# CONTROLSS_G2_EPWM20_CONTROLSS_G2_EPWM20 register map
Vendor: Texas Instruments
Registers are 16-bit, read-write, reset 0x0 unless marked. A register's access mark holds for its fields unless they carry their own. Offsets are as the file gives them; [hi:lo] are bit positions; {n}, {i} and the like mark numbered series.

## CONTROLSS_G2_EPWM20_CONTROLSS_G2_EPWM (part 4 of 4)
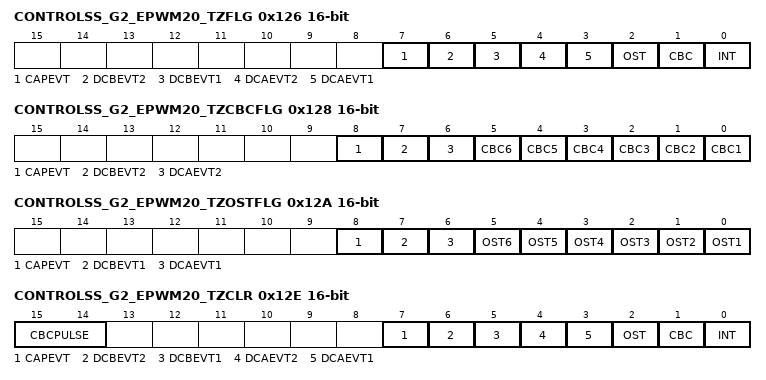
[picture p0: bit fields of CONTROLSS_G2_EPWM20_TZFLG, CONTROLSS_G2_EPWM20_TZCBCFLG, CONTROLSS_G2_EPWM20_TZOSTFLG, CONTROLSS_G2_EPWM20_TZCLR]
0x126 CONTROLSS_G2_EPWM20_TZFLG ro — Trip Zone Flag Register
  [7] CAPEVT — Latched Status Flag for Capture Event 0: Indicates no trip event has occurred on CAPEVT 1: Indicates a trip event has occurred for the event defined for CAPEVT
  [6] DCBEVT2 — Latched Status Flag for Digital Compare Output B Event 2 0: Indicates no trip event has occurred on DCBEVT2 1: Indicates a trip event has occurred for the event defined for DCBEVT2
  [5] DCBEVT1 — Latched Status Flag for Digital Compare Output B Event 1 0: Indicates no trip event has occurred on DCBEVT1 1: Indicates a trip event has occurred for the event defined for DCBEVT1
  [4] DCAEVT2 — Latched Status Flag for Digital Compare Output A Event 2 0: Indicates no trip event has occurred on DCAEVT2 1: Indicates a trip event has occurred for the event defined for DCAEVT2
  [3] DCAEVT1 — Latched Status Flag for Digital Compare Output A Event 1 0: Indicates no trip event has occurred on DCAEVT1 1: Indicates a trip event has occurred for the event defined for DCAEVT1
  [2] OST — Latched Status Flag for A One-Shot Trip Event 0: No one-shot trip event has occurred. 1: Indicates a trip event has occurred on a pin selected as a one-shot trip source. This bit is cleared by writing the appropriate value to the TZCLR register.
  [1] CBC — Latched Status Flag for Cycle-By-Cycle Trip Event 0: No cycle-by-cycle trip event has occurred. 1: Indicates a trip event has occurred on a signal selected as a cycle-by-cycle trip source. The TZFLG[CBC] bit will remain set until it is manually cleared by the user. If the cycle-by-cycle trip event is still present when the CBC bit is cleared, then CBC will be immediately set again. The specified condition on the signal is automatically cleared when the ePWM time-base counter reaches zero [TBCTR = 0x00] if the trip condition is no longer present. The condition on the signal is only cleared when the TBCTR = 0x00 no matter where in the cycle the CBC flag is cleared. This bit is cleared by writing the appropriate value to the TZCLR register.
  [0] INT — Latched Trip Interrupt Status Flag 0: Indicates no interrupt has been generated. 1: Indicates an EPWMx_TZINT PIE interrupt was generated because of a trip condition. No further EPWMx_TZINT PIE interrupts will be generated until this flag is cleared. If the interrupt flag is cleared when either CBC or OST is set, then another interrupt pulse will be generated. Clearing all flag bits will prevent further interrupts. This bit is cleared by writing the appropriate value to the TZCLR register.
0x128 CONTROLSS_G2_EPWM20_TZCBCFLG ro — Trip Zone CBC Flag Register
  [8] CAPEVT — Latched Status Flag for Capture Event 0: Indicates no trip event has occurred on CAPEVT 1: Indicates a trip event has occurred for the event defined for CAPEVT
  [7] DCBEVT2 — Latched Status Flag for Digital Compare B Output Event 2 Trip Latch 0: Reading a 0 indicates that no trip has occurred on DCBEVT2. 1: Reading a 1 indicates a trip has occured on the DCBEVT2 selected event.
  [6] DCAEVT2 — Latched Status Flag for Digital Compare A Output Event 2 Trip Latch 0: Reading a 0 indicates that no trip has occurred on DCAEVT2. 1: Reading a 1 indicates a trip has occured on the DCAEVT2 selected event.
  [n-1] CBC{n} (n=1..6) — Latched Status Flag for CBC{n} Trip Latch 0: Reading a 0 indicates that no trip has occurred on CBC{n}. 1: Reading a 1 indicates a trip has occured on the CBC{n} selected event.
0x12A CONTROLSS_G2_EPWM20_TZOSTFLG ro — Trip Zone OST Flag Register
  [8] CAPEVT — Latched Status Flag for Capture Event 0: Indicates no trip event has occurred on CAPEVT 1: Indicates a trip event has occurred for the event defined for CAPEVT
  [7] DCBEVT1 — Latched Status Flag for Digital Compare B Output Event 1 Trip Latch 0: Reading a 0 indicates that no trip has occurred on DCBEVT1. 1: Reading a 1 indicates a trip has occured on the DCBEVT1 selected event.
  [6] DCAEVT1 — Latched Status Flag for Digital Compare A Output Event 1 Trip Latch 0: Reading a 0 indicates that no trip has occurred on DCAEVT1. 1: Reading a 1 indicates a trip has occured on the DCAEVT1 selected event.
  [n-1] OST{n} (n=1..6) — Latched Status Flag for OST{n} Trip Latch 0: Reading a 0 indicates that no trip has occurred on OST{n}. 1: Reading a 1 indicates a trip has occured on the OST{n} selected event.
0x12E CONTROLSS_G2_EPWM20_TZCLR access not given — Trip Zone Clear Register
  [15:14] CBCPULSE rw — Clear Pulse for Cycle-By-Cycle [CBC] Trip Latch This bit field determines which pulse clears the CBC trip latch. 00: CTR = zero pulse clears CBC trip latch. [Same as legacy designs.] 01: CTR = PRD pulse clears CBC trip latch. 10: CTR = zero or CTR = PRD pulse clears CBC trip latch. 11: CBC trip latch is not cleared
  [7] CAPEVT — Clear Flag for Capture Event 0: Writing 0 has no effect. This bit always reads back 0. 1: Writing 1 clears the CAPEVT event trip condition. (access R/W1TS)
  [6] DCBEVT2 — Clear Flag for Digital Compare Output B Event 2 0: Writing 0 has no effect. This bit always reads back 0. 1: Writing 1 clears the DCBEVT2 event trip condition. (access R/W1TS)
  [5] DCBEVT1 — Clear Flag for Digital Compare Output B Event 1 0: Writing 0 has no effect. This bit always reads back 0. 1: Writing 1 clears the DCBEVT1 event trip condition. (access R/W1TS)
  [4] DCAEVT2 — Clear Flag for Digital Compare Output A Event 2 0: Writing 0 has no effect. This bit always reads back 0. 1: Writing 1 clears the DCAEVT2 event trip condition. (access R/W1TS)
  [3] DCAEVT1 — Clear Flag for Digital Compare Output A Event 1 0: Writing 0 has no effect. This bit always reads back 0. 1: Writing 1 clears the DCAEVT1 event trip condition. (access R/W1TS)
  [2] OST — Clear Flag for One-Shot Trip [OST] Latch 0: Has no effect. Always reads back a 0. 1: Clears this Trip [set] condition. (access R/W1TS)
  [1] CBC — Clear Flag for Cycle-By-Cycle [CBC] Trip Latch 0: Has no effect. Always reads back a 0. 1: Clears this Trip [set] condition. (access R/W1TS)
  [0] INT — Global Interrupt Clear Flag 0: Has no effect. Always reads back a 0. 1: Clears the trip-interrupt flag for this ePWM module [TZFLG[INT]]. NOTE: No further EPWMx_TZINT PIE interrupts will be generated until the flag is cleared. If the TZFLG[INT] bit is cleared and any of the other flag bits are set, then another interrupt pulse will be generated. Clearing all flag bits will prevent further interrupts. (access R/W1TS)
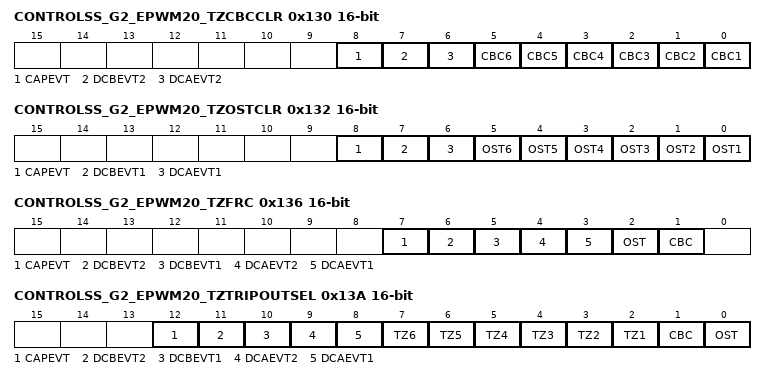
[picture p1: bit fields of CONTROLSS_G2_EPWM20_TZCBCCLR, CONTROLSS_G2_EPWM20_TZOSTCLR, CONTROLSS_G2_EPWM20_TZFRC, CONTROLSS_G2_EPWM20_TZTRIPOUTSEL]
0x130 CONTROLSS_G2_EPWM20_TZCBCCLR access not given — Trip Zone CBC Clear Register
  [8] CAPEVT — Clear Flag for CAPEVT selected for CBC 0: Writing a 0 has no effect. 1: Writing a 1 will clear the TZCBCFLG[CAPEVT] bit. (access R/W1TS)
  [7] DCBEVT2 — Clear Flag for Digital Compare Output B Event 2 selected for CBC 0: Writing a 0 has no effect. 1: Writing a 1 will clear the TZCBCFLG[DCBEVT2] bit. (access R/W1TS)
  [6] DCAEVT2 — Clear Flag for Digital Compare Output A Event 2 selected for CBC 0: Writing a 0 has no effect. 1: Writing a 1 will clear the TZCBCFLG[DCAEVT2] bit. (access R/W1TS)
  [n-1] CBC{n} (n=1..6) — Clear Flag for Cycle-By-Cycle [CBC{n}] Trip Latch 0: Writing a 0 has no effect. 1: Writing a 1 will clear the TZCBCFLG[CBC{n}] bit. (access R/W1TS)
0x132 CONTROLSS_G2_EPWM20_TZOSTCLR access not given — Trip Zone OST Clear Register
  [8] CAPEVT — Clear Flag for CAPEVT selected for OST 0: Writing a 0 has no effect. 1: Writing a 1 will clear the TZOSTFLG[CAPEVT] bit. (access R/W1TS)
  [7] DCBEVT1 — Clear Flag for Digital Compare Output B Event 1 selected for OST 0: Writing a 0 has no effect. 1: Writing a 1 will clear the TZOSTFLG[DCBEVT1] bit. (access R/W1TS)
  [6] DCAEVT1 — Clear Flag for Digital Compare Output A Event 1 selected for OST 0: Writing a 0 has no effect. 1: Writing a 1 will clear the TZOSTFLG[DCAEVT1] bit. (access R/W1TS)
  [n-1] OST{n} (n=1..6) — Clear Flag for Oneshot [OST{n}] Trip Latch 0: Writing a 0 has no effect. 1: Writing a 1 will clear the TZOSTFLG[OST{n}] bit. (access R/W1TS)
0x136 CONTROLSS_G2_EPWM20_TZFRC access not given — Trip Zone Force Register
  [7] CAPEVT — Force Flag for Capture Event Output 0: Writing 0 has no effect. This bit always reads back 0. 1: Writing 1 forces the CAPEVT event trip condition and sets the TZFLG[CAPEVT] bit. (access R/W1TS)
  [6] DCBEVT2 — Force Flag for Digital Compare Output B Event 2 0: Writing 0 has no effect. This bit always reads back 0. 1: Writing 1 forces the DCBEVT2 event trip condition and sets the TZFLG[DCBEVT2] bit. (access R/W1TS)
  [5] DCBEVT1 — Force Flag for Digital Compare Output B Event 1 0: Writing 0 has no effect. This bit always reads back 0. 1: Writing 1 forces the DCBEVT1 event trip condition and sets the TZFLG[DCBEVT1] bit. (access R/W1TS)
  [4] DCAEVT2 — Force Flag for Digital Compare Output A Event 2 0: Writing 0 has no effect. This bit always reads back 0. 1: Writing 1 forces the DCAEVT2 event trip condition and sets the TZFLG[DCAEVT2] bit. (access R/W1TS)
  [3] DCAEVT1 — Force Flag for Digital Compare Output A Event 1 0: Writing 0 has no effect. This bit always reads back 0 1: Writing 1 forces the DCAEVT1 event trip condition and sets the TZFLG[DCAEVT1] bit. (access R/W1TS)
  [2] OST — Force a One-Shot Trip Event via Software 0: Writing of 0 is ignored. Always reads back a 0. 1: Forces a one-shot trip event and sets the TZFLG[OST] bit. (access R/W1TS)
  [1] CBC — Force a Cycle-by-Cycle Trip Event via Software 0: Writing of 0 is ignored. Always reads back a 0. 1: Forces a cycle-by-cycle trip event and sets the TZFLG[CBC] bit. (access R/W1TS)
0x13A CONTROLSS_G2_EPWM20_TZTRIPOUTSEL — Trip Zone Force Register
  [12] CAPEVT — CAPEVT Select 0: Disable TZ6 as a TRIPOUT source for this ePWM module 1: Enable TZ6 as a TRIPOUT source for this ePWM module
  [11] DCBEVT2 — DCBEVT2 Select 0: Disable TZ6 as a TRIPOUT source for this ePWM module 1: Enable TZ6 as a TRIPOUT source for this ePWM module
  [10] DCBEVT1 — DCBEVT1 Select 0: Disable TZ6 as a TRIPOUT source for this ePWM module 1: Enable TZ6 as a TRIPOUT source for this ePWM module
  [9] DCAEVT2 — DCAEVT2 Select 0: Disable TZ6 as a TRIPOUT source for this ePWM module 1: Enable TZ6 as a TRIPOUT source for this ePWM module
  [8] DCAEVT1 — DCAEVT1 Select 0: Disable TZ6 as a TRIPOUT source for this ePWM module 1: Enable TZ6 as a TRIPOUT source for this ePWM module
  [n+1] TZ{n} (n=1..6) — Trip-zone {n} [TZ{n}] Select 0: Disable TZ{n} as a TRIPOUT source for this ePWM module 1: Enable TZ{n} as a TRIPOUT source for this ePWM module
  [1] CBC — CBC Select 0: Disable TZ1 as a TRIPOUT source for this ePWM module 1: Enable TZ1 as a TRIPOUT source for this ePWM module
  [0] OST — OST Select 0: Disable TZ1 as a TRIPOUT source for this ePWM module 1: Enable TZ1 as a TRIPOUT source for this ePWM module
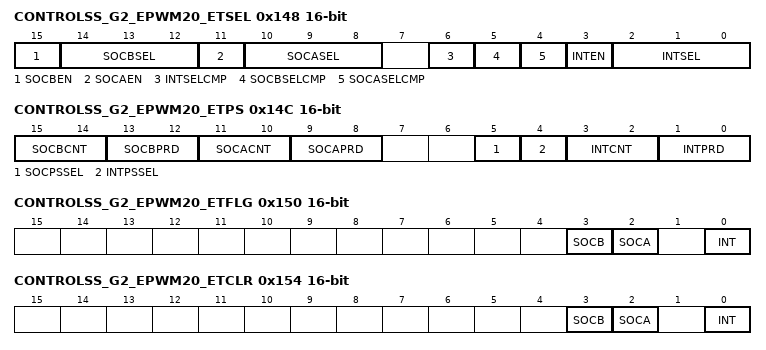
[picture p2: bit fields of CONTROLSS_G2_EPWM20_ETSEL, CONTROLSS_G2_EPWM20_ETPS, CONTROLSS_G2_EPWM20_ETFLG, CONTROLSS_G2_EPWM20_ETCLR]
0x148 CONTROLSS_G2_EPWM20_ETSEL — Event Trigger Selection Register
  [15] SOCBEN — Enable the ADC Start of Conversion B [EPWMxSOCB] Pulse 0: Disable EPWMxSOCB. 1: Enable EPWMxSOCB pulse.
  [14:12] SOCBSEL — EPWMxSOCB Selection Options These bits determine when a EPWMxSOCB pulse will be generated. 000: Enable DCBEVT1.soc event 001: Enable event time-base counter equal to zero. [TBCTR = 0x00] 010: Enable event time-base counter equal to period [TBCTR = TBPRD] 011: Enable event time-base counter based on mixed events [ETSOCBMIX]. ETSOCBMIX is configured in the ETSOCBMIXEN register. 100: Enable event time-base counter equal to CMPA when the timer is incrementing or CMPC when the timer is incrementing 101: Enable event time-base counter equal to CMPA when the timer is decrementing or CMPC when the timer is decrementing 110: Enable event: time-base counter equal to CMPB when the timer is incrementing or CMPD when the timer is incrementing 111: Enable event: time-base counter equal to CMPB when the timer is decrementing or CMPD when the timer is decrementing [*] Event selected is determined by SOCBSELCMP bit.
  [11] SOCAEN — Enable the ADC Start of Conversion A [EPWMxSOCA] Pulse 0: Disable EPWMxSOCA. 1: Enable EPWMxSOCA pulse.
  [10:8] SOCASEL — EPWMxSOCA Selection Options These bits determine when a EPWMxSOCA pulse will be generated. 000: Enable DCAEVT1.soc event 001: Enable event time-base counter equal to zero. [TBCTR = 0x00] 010: Enable event time-base counter equal to period [TBCTR = TBPRD] 011: Enable event time-base counter based on mixed events [ETSOCAMIX]. ETSOCAMIX is configured in the ETSOCAMIXEN register. 100: Enable event time-base counter equal to CMPA when the timer is incrementing or CMPC when the timer is incrementing 101: Enable event time-base counter equal to CMPA when the timer is decrementing or CMPC when the timer is decrementing 110: Enable event: time-base counter equal to CMPB when the timer is incrementing or CMPD when the timer is incrementing 111: Enable event: time-base counter equal to CMPB when the timer is decrementing or CMPD when the timer is decrementing [*] Event selected is determined by SOCASELCMP bit.
  [6] INTSELCMP — EPWMxINT Compare Register Selection Options 0: Enable event time-base counter equal to CMPA when the timer is incrementing / Enable event time-base counter equal to CMPA when the timer is decrementing / Enable event: time-base counter equal to CMPB when the timer is incrementing / Enable event: time-base counter equal to CMPB when the timer is decrementing to INTSEL selection mux. 1: Enable event time-base counter equal to CMPC when the timer is incrementing / Enable event time-base counter equal to CMPC when the timer is decrementing / Enable event: time-base counter equal to CMPD when the timer is incrementing / Enable event: time-base counter equal to CMPD when the timer is decrementing to INTSEL selection mux.
  [5] SOCBSELCMP — EPWMxSOCB Compare Register Selection Options 0: Enable event time-base counter equal to CMPA when the timer is incrementing / Enable event time-base counter equal to CMPA when the timer is decrementing / Enable event: time-base counter equal to CMPB when the timer is incrementing / Enable event: time-base counter equal to CMPB when the timer is decrementing to SOCBSEL selection mux. 1: Enable event time-base counter equal to CMPC when the timer is incrementing / Enable event time-base counter equal to CMPC when the timer is decrementing / Enable event: time-base counter equal to CMPD when the timer is incrementing / Enable event: time-base counter equal to CMPD when the timer is decrementing to SOCBSEL selection mux.
  [4] SOCASELCMP — EPWMxSOCA Compare Register Selection Options 0: Enable event time-base counter equal to CMPA when the timer is incrementing / Enable event time-base counter equal to CMPA when the timer is decrementing / Enable event: time-base counter equal to CMPB when the timer is incrementing / Enable event: time-base counter equal to CMPB when the timer is decrementing to SOCASEL selection mux. 1: Enable event time-base counter equal to CMPC when the timer is incrementing / Enable event time-base counter equal to CMPC when the timer is decrementing / Enable event: time-base counter equal to CMPD when the timer is incrementing / Enable event: time-base counter equal to CMPD when the timer is decrementing to SOCASEL selection mux.
  [3] INTEN — Enable ePWM Interrupt [EPWMx_INT] Generation 0: Disable EPWMx_INT generation 1: Enable EPWMx_INT generation
  [2:0] INTSEL — ePWM Interrupt [EPWMx_INT] Selection Options 000: Reserved 001: Enable event time-base counter equal to zero. [TBCTR = 0x00] 010: Enable event time-base counter equal to period [TBCTR = TBPRD] 011: Enable event time-base counter based on mixed events [ETINTMIX]. ETINTMIX is configured in the ETINTMIXEN register. 100: Enable event time-base counter equal to CMPA when the timer is incrementing or CMPC when the timer is incrementing 101: Enable event time-base counter equal to CMPA when the timer is decrementing or CMPC when the timer is decrementing 110: Enable event: time-base counter equal to CMPB when the timer is incrementing or CMPD when the timer is incrementing 111: Enable event: time-base counter equal to CMPB when the timer is decrementing or CMPD when the timer is decrementing [*] Event selected is determined by INTSELCMP bit.
0x14C CONTROLSS_G2_EPWM20_ETPS access per field — Event Trigger Pre-Scale Register
  [15:14] SOCBCNT ro — ePWM ADC Start-of-Conversion B Event [EPWMxSOCB] Counter Register These bits indicate how many selected ETSEL[SOCBSEL] events have occurred: 00: No events have occurred. 01: 1 event has occurred. 10: 2 events have occurred. 11: 3 events have occurred.
  [13:12] SOCBPRD rw — ePWM ADC Start-of-Conversion B Event [EPWMxSOCB] Period Select These bits determine how many selected ETSEL[SOCBSEL] events need to occur before an EPWMxSOCB pulse is generated. To be generated, the pulse must be enabled [ETSEL[SOCBEN] = 1]. The SOCB pulse will be generated even if the status flag is set from a previous start of conversion [ETFLG[SOCB] = 1]. Once the SOCB pulse is generated, the ETPS[SOCBCNT] bits will automatically be cleared. 00: Disable the SOCB event counter. No EPWMxSOCB pulse will be generated 01: Generate the EPWMxSOCB pulse on the first event: ETPS[SOCBCNT] = 0,1 10: Generate the EPWMxSOCB pulse on the second event: ETPS[SOCBCNT] = 1,0 11: Generate the EPWMxSOCB pulse on the third event: ETPS[SOCBCNT] = 1,1
  [11:10] SOCACNT ro — ePWM ADC Start-of-Conversion A Event [EPWMxSOCA] Counter Register These bits indicate how many selected ETSEL[SOCASEL] events have occurred: 00: No events have occurred. 01: 1 event has occurred. 10: 2 events have occurred. 11: 3 events have occurred.
  [9:8] SOCAPRD rw — ePWM ADC Start-of-Conversion A Event [EPWMxSOCA] Period Select These bits determine how many selected ETSEL[SOCASEL] events need to occur before an EPWMxSOCA pulse is generated. To be generated, the pulse must be enabled [ETSEL[SOCAEN] = 1]. The SOCA pulse will be generated even if the status flag is set from a previous start of conversion [ETFLG[SOCA] = 1]. Once the SOCA pulse is generated, the ETPS[SOCACNT] bits will automatically be cleared. 00: Disable the SOCA event counter. No EPWMxSOCA pulse will be generated 01: Generate the EPWMxSOCA pulse on the first event: ETPS[SOCACNT] = 0,1 10: Generate the EPWMxSOCA pulse on the second event: ETPS[SOCACNT] = 1,0 11: Generate the EPWMxSOCA pulse on the third event: ETPS[SOCACNT] = 1,1
  [5] SOCPSSEL rw — EPWMxSOC A/B Pre-Scale Selection Bits 0: Selects ETPS [SOCACNT/SOCBCNT] and [SOCAPRD/SOCBPRD] registers to determine frequency of events [interrupt once every 0-3 events]. 1: Selects ETSOCPS [SOCACNT2/SOCBCNT2] and [SOCAPRD2/SOCBPRD2] registers to determine frequency of events [interrupt once every 0-15 events].
  [4] INTPSSEL rw — EPWMxINTn Pre-Scale Selection Bits 0: Selects ETPS [INTCNT, and INTPRD] registers to determine frequency of events [interrupt once every 0-3 events]. 1: Selects ETINTPS [ INTCNT2, and INTPRD2 ] registers to determine frequency of events [interrupt once every 0-15 events].
  [3:2] INTCNT ro — ePWM Interrupt Event [EPWMx_INT] Counter Register These bits indicate how many selected ETSEL[INTSEL] events have occurred. These bits are automatically cleared when an interrupt pulse is generated. If interrupts are disabled, ETSEL[INT] = 0 or the interrupt flag is set, ETFLG[INT] = 1, the counter will stop counting events when it reaches the period value ETPS[INTCNT] = ETPS[INTPRD]. 00: No events have occurred. 01: 1 event has occurred. 10: 2 events have occurred. 11: 3 events have occurred.
  [1:0] INTPRD rw — ePWM Interrupt [EPWMx_INT] Period Select These bits determine how many selected ETSEL[INTSEL] events need to occur before an interrupt is generated. To be generated, the interrupt must be enabled [ETSEL[INT] = 1]. If the interrupt status flag is set from a previous interrupt [ETFLG[INT] = 1] then no interrupt will be generated until the flag is cleared via the ETCLR[INT] bit. This allows for one interrupt to be pending while another is still being serviced. Once the interrupt is generated, the ETPS[INTCNT] bits will automatically be cleared. Writing a INTPRD value that is the same as the current counter value will trigger an interrupt if it is enabled and the status flag is clear. Writing a INTPRD value that is less than the current counter value will result in an undefined state. If a counter event occurs at the same instant as a new zero or non-zero INTPRD value is written, the counter is incremented. 00: Disable the interrupt event counter. No interrupt will be generated and ETFRC[INT] is ignored. 01: Generate an interrupt on the first event INTCNT = 01 [first event] 10: Generate interrupt on ETPS[INTCNT] = 1,0 [second event] 11: Generate interrupt on ETPS[INTCNT] = 1,1 [third event]
0x150 CONTROLSS_G2_EPWM20_ETFLG ro — Event Trigger Flag Register
  [3] SOCB — Latched ePWM ADC Start-of-Conversion A [EPWMxSOCB] Status Flag Unlike the ETFLG[INT] flag, the EPWMxSOCB output will continue to pulse even if the flag bit is set. 0: Indicates no event occurred 1: Indicates that a start of conversion pulse was generated on EPWMxSOCB. The EPWMxSOCB output will continue to be generated even if the flag bit is set.
  [2] SOCA — Latched ePWM ADC Start-of-Conversion A [EPWMxSOCA] Status Flag Unlike the ETFLG[INT] flag, the EPWMxSOCA output will continue to pulse even if the flag bit is set. 0: Indicates no event occurred 1: Indicates that a start of conversion pulse was generated on EPWMxSOCA. The EPWMxSOCA output will continue to be generated even if the flag bit is set.
  [0] INT — Latched ePWM Interrupt [EPWMx_INT] Status Flag 0: Indicates no event occurred 1: Indicates that an ePWMx interrupt [EPWMx_INT] was generated. No further interrupts will be generated until the flag bit is cleared. Up to one interrupt can be pending while the ETFLG[INT] bit is still set. If an interrupt is pending, it will not be generated until after the ETFLG[INT] bit is cleared.
0x154 CONTROLSS_G2_EPWM20_ETCLR access not given — Event Trigger Clear Register
  [3] SOCB — ePWM ADC Start-of-Conversion A [EPWMxSOCB] Flag Clear Bit 0: Writing a 0 has no effect. Always reads back a 0 1: Clears the ETFLG[SOCB] flag bit (access R/W1TS)
  [2] SOCA — ePWM ADC Start-of-Conversion A [EPWMxSOCA] Flag Clear Bit 0: Writing a 0 has no effect. Always reads back a 0 1: Clears the ETFLG[SOCA] flag bit (access R/W1TS)
  [0] INT — ePWM Interrupt [EPWMx_INT] Flag Clear Bit 0: Writing a 0 has no effect. Always reads back a 0 1: Clears the ETFLG[INT] flag bit and enable further interrupts pulses to be generated (access R/W1TS)
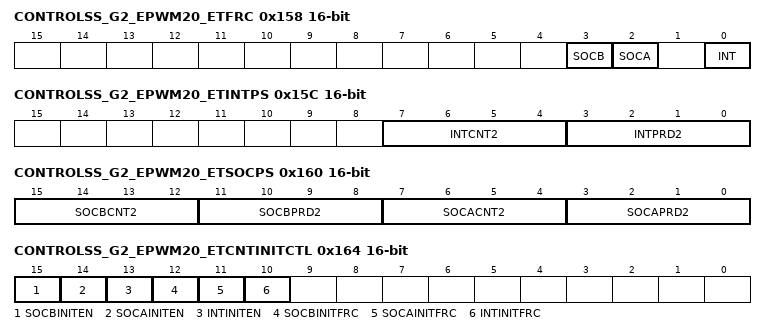
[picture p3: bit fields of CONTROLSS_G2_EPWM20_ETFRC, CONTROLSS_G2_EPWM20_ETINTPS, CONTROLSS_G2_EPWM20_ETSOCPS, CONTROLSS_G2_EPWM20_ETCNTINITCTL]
0x158 CONTROLSS_G2_EPWM20_ETFRC access not given — Event Trigger Force Register
  [3] SOCB — SOCB Force Bit The SOCB pulse will only be generated if the event is enabled in the ETSEL register. The ETFLG[SOCB] flag bit will be set regardless. 0: Writing 0 to this bit will be ignored. Always reads back a 0. 1: Generates a pulse on EPWMxSOCB and set the SOCBFLG bit. This bit is used for test purposes. (access R/W1TS)
  [2] SOCA — SOCA Force Bit The SOCA pulse will only be generated if the event is enabled in the ETSEL register. The ETFLG[SOCA] flag bit will be set regardless. 0: Writing 0 to this bit will be ignored. Always reads back a 0. 1: Generates a pulse on EPWMxSOCA and set the SOCAFLG bit. This bit is used for test purposes. (access R/W1TS)
  [0] INT — INT Force Bit The interrupt will only be generated if the event is enabled in the ETSEL register. The INT flag bit will be set regardless. 0: Writing 0 to this bit will be ignored. Always reads back a 0. 1: Generates an interrupt on EPWMxINT and set the INT flag bit. This bit is used for test purposes. (access R/W1TS)
0x15C CONTROLSS_G2_EPWM20_ETINTPS access per field — Event-Trigger Interrupt Pre-Scale Register
  [7:4] INTCNT2 ro — EPWMxINT Counter 2 When ETPS[INTPSSEL]=1, these bits indicate how many selected events have occurred: 0000: No events 0001: 1 event 0010: 2 events 0011: 3 events 0100: 4 events ... 1111: 15 events
  [3:0] INTPRD2 rw — EPWMxINT Period 2 Select When ETPS[INTPSSEL] = 1, these bits select how many selected events need to occur before an interrupt is generated: 0000: Disable counter 0001: Generate interrupt on INTCNT = 1 [first event] 0010: Generate interrupt on INTCNT = 2 [second event] 0011: Generate interrupt on INTCNT = 3 [third event] 0100: Generate interrupt on INTCNT = 4 [fourth event] ... 1111: Generate interrupt on INTCNT = 15 [fifteenth event]
0x160 CONTROLSS_G2_EPWM20_ETSOCPS access per field — Event-Trigger SOC Pre-Scale Register
  [15:12] SOCBCNT2 ro — EPWMxSOCB Counter 2 When ETPS[SOCPSSEL] = 1, these bits indicate how many selected events have occurred: 0000: No events 0001: 1 event 0010: 2 events 0011: 3 events 0100: 4 events ... 1111: 15 events
  [11:8] SOCBPRD2 rw — EPWMxSOCB Period 2 Select When ETPS[SOCPSSEL] = 1, these bits select how many selected event need to occur before an SOCB pulse is generated: 0000: Disable counter 0001: Generate interrupt on SOCBCNT2 = 1 [first event] 0010: Generate interrupt on SOCBCNT2 = 2 [second event] 0011: Generate interrupt on SOCBCNT2 = 3 [third event] 0100: Generate interrupt on SOCBCNT2 = 4 [fourth event] ... 1111: Generate interrupt on SOCBCNT2 = 15 [fifteenth event]
  [7:4] SOCACNT2 ro — EPWMxSOCA Counter 2 When ETPS[SOCPSSEL] = 1, these bits indicate how many selected events have occurred: 0000: No events 0001: 1 event 0010: 2 events 0011: 3 events 0100: 4 events ... 1111: 15 events
  [3:0] SOCAPRD2 rw — EPWMxSOCA Period 2 Select When ETPS[SOCPSSEL] = 1, these bits select how many selected event need to occur before an SOCA pulse is generated: 0000: Disable counter 0001: Generate interrupt on SOCACNT2 = 1 [first event] 0010: Generate interrupt on SOCACNT2 = 2 [second event] 0011: Generate interrupt on SOCACNT2 = 3 [third event] 0100: Generate interrupt on SOCACNT2 = 4 [fourth event] ... 1111: Generate interrupt on SOCACNT2 = 15 [fifteenth event]
0x164 CONTROLSS_G2_EPWM20_ETCNTINITCTL access not given — Event-Trigger Counter Initialization Control Register
  [15] SOCBINITEN rw — EPWMxSOCB Counter 2 Initialization Enable 0: Has no effect. 1: Enable initialization of EPWMxSOCB counter with contents of ETCNTINIT[SOCBINIT] on a SYNC event or software force.
  [14] SOCAINITEN rw — EPWMxSOCA Counter 2 Initialization Enable 0: Has no effect. 1: Enable initialization of EPWMxSOCA counter with contents of ETCNTINIT[SOCAINIT] on a SYNC event or software force.
  [13] INTINITEN rw — EPWMxINT Counter 2 Initialization Enable 0: Has no effect. 1: Enable initialization of EPWMxINT counter 2 with contents of ETCNTINIT[INTINIT] on a SYNC event or software force.
  [12] SOCBINITFRC — EPWMxSOCB Counter 2 Initialization Force 0: Has no effect. 1: This bit forces the ET EPWMxSOCB counter to be initialized with the contents of ETCNTINIT[SOCBINIT]. (access R/W1TS)
  [11] SOCAINITFRC — EPWMxSOCA Counter 2 Initialization Force 0: Has no effect. 1: This bit forces the ET EPWMxSOCA counter to be initialized with the contents of ETCNTINIT[SOCAINIT]. (access R/W1TS)
  [10] INTINITFRC — EPWMxINT Counter 2 Initialization Force 0: Has no effect. 1: This bit forces the ET EPWMxINT counter to be initialized with the contents of ETCNTINIT[INTINIT]. (access R/W1TS)
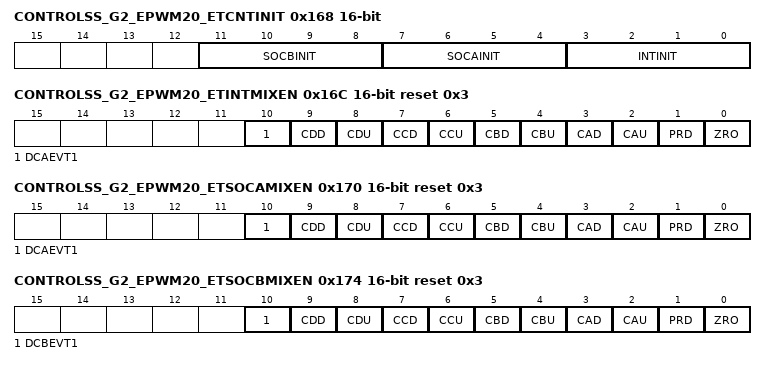
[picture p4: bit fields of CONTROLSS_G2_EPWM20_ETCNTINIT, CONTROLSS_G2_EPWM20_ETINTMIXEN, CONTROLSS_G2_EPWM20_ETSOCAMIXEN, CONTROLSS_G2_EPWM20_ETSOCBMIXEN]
0x168 CONTROLSS_G2_EPWM20_ETCNTINIT — Event-Trigger Counter Initialization Register
  [11:8] SOCBINIT — EPWMxSOCB Counter 2 Initialization Bits The ET EPWMxSOCB counter is initialized with the contents of this register on an ePWM SYNC event or a software force.
  [7:4] SOCAINIT — EPWMxSOCA Counter 2 Initialization Bits The ET EPWMxSOCA counter is initialized with the contents of this register on an ePWM SYNC event or a software force.
  [3:0] INTINIT — EPWMxINT Counter 2 Initialization Bits The ET EPWMxINT counter is initialized with the contents of this register on an ePWM SYNC event or a software force.
0x16C CONTROLSS_G2_EPWM20_ETINTMIXEN reset 0x3 — Event-Trigger Mixed INT Selection
  [10] DCAEVT1 — Enable DCAEVT1.inter to the mixed ET interrupt trigger signal [ETINTMIX]. 0: DCAEVT1.soc event is not enabled 1: Enable DCAEVT1.soc event
  [9] CDD — Enable event time-base counter equal to CMPD when the timer is decrementing to the mixed ET interrupt trigger signal [ETINTMIX]. 0: CMPD down-count match enable event is not enabled 1: Enable CMPD down-count match enable event
  [8] CDU — Enable event time-base counter equal to CMPD when the timer is incrementing to the mixed ET interrupt trigger signal [ETINTMIX]. 0: CMPD up-count match enable event is not enabled 1: Enable CMPD up-count match enable event
  [7] CCD — Enable event time-base counter equal to CMPC when the timer is decrementing to the mixed ET interrupt trigger signal [ETINTMIX]. 0: CMPC down-count match enable event is not enabled 1: Enable CMPC down-count match enable event
  [6] CCU — Enable event time-base counter equal to CMPC when the timer is incrementing to the mixed ET interrupt trigger signal [ETINTMIX]. 0: CMPC up-count match enable event is not enabled 1: Enable CMPC up-count match enable event
  [5] CBD — Enable event time-base counter equal to CMPB when the timer is decrementing to the mixed ET interrupt trigger signal [ETINTMIX]. 0: CMPB down-count match enable event is not enabled 1: Enable CMPB down-count match enable event
  [4] CBU — Enable event time-base counter equal to CMPB when the timer is incrementing to the mixed ET interrupt trigger signal [ETINTMIX]. 0: CMPB up-count match enable event is not enabled 1: Enable CMPB up-count match enable event
  [3] CAD — Enable event time-base counter equal to CMPA when the timer is decrementing to the mixed ET interrupt trigger signal [ETINTMIX]. 0: CMPA down-count match enable event is not enabled 1: Enable CMPA down-count match enable event
  [2] CAU — Enable event time-base counter equal to CMPA when the timer is incrementing to the mixed ET interrupt trigger signal [ETINTMIX]. 0: CMPA up-count match enable event is not enabled 1: Enable CMPA up-count match enable event
  [1] PRD — Enable event time-base counter equal to period [TBCTR = TBPRD] to the mixed ET interrupt trigger signal [ETINTMIX]. 0: Period match event is not enabled 1: Enable period match event
  [0] ZRO — Enable event time-base counter equal to zero [TBCTR = 0x00] to the mixed ET interrupt trigger signal [ETINTMIX]. 0: Zero match event is not enabled 1: Enable zero match event
0x170 CONTROLSS_G2_EPWM20_ETSOCAMIXEN reset 0x3 — Event-Trigger Mixed SOCA Selection
  [10] DCAEVT1 — Enable DCAEVT1.inter to the mixed ET SOCA trigger signal [ETSOCAMIX]. 0: DCAEVT1.soc event is not enabled 1: Enable DCAEVT1.soc event
  [9] CDD — Enable event time-base counter equal to CMPD when the timer is decrementing to the mixed ET SOCA trigger signal [ETSOCAMIX]. 0: CMPD down-count match enable event is not enabled 1: Enable CMPD down-count match enable event
  [8] CDU — Enable event time-base counter equal to CMPD when the timer is incrementing to the mixed ET SOCA trigger signal [ETSOCAMIX]. 0: CMPD up-count match enable event is not enabled 1: Enable CMPD up-count match enable event
  [7] CCD — Enable event time-base counter equal to CMPC when the timer is decrementing to the mixed ET SOCA trigger signal [ETSOCAMIX]. 0: CMPC down-count match enable event is not enabled 1: Enable CMPC down-count match enable event
  [6] CCU — Enable event time-base counter equal to CMPC when the timer is incrementing to the mixed ET SOCA trigger signal [ETSOCAMIX]. 0: CMPC up-count match enable event is not enabled 1: Enable CMPC up-count match enable event
  [5] CBD — Enable event time-base counter equal to CMPB when the timer is decrementing to the mixed ET SOCA trigger signal [ETSOCAMIX]. 0: CMPB down-count match enable event is not enabled 1: Enable CMPB down-count match enable event
  [4] CBU — Enable event time-base counter equal to CMPB when the timer is incrementing to the mixed ET SOCA trigger signal [ETSOCAMIX]. 0: CMPB up-count match enable event is not enabled 1: Enable CMPB up-count match enable event
  [3] CAD — Enable event time-base counter equal to CMPA when the timer is decrementing to the mixed ET SOCA trigger signal [ETSOCAMIX]. 0: CMPA down-count match enable event is not enabled 1: Enable CMPA down-count match enable event
  [2] CAU — Enable event time-base counter equal to CMPA when the timer is incrementing to the mixed ET SOCA trigger signal [ETSOCAMIX]. 0: CMPA up-count match enable event is not enabled 1: Enable CMPA up-count match enable event
  [1] PRD — Enable event time-base counter equal to period [TBCTR = TBPRD] to the mixed ET SOCA trigger signal [ETSOCAMIX]. 0: Period match event is not enabled 1: Enable period match event
  [0] ZRO — Enable event time-base counter equal to zero [TBCTR = 0x00] to the mixed ET SOCA trigger signal [ETSOCAMIX]. 0: Zero match event is not enabled 1: Enable zero match event
0x174 CONTROLSS_G2_EPWM20_ETSOCBMIXEN reset 0x3 — Event-Trigger Mixed SOCB Selection
  [10] DCBEVT1 — Enable DCBEVT1.inter to the mixed ET SOCB trigger signal [ETSOCBMIX]. 0: DCBEVT1.soc event is not enabled 1: Enable DCBEVT1.soc event
  [9] CDD — Enable event time-base counter equal to CMPD when the timer is decrementing to the mixed ET SOCB trigger signal [ETSOCBMIX]. 0: CMPD down-count match enable event is not enabled 1: Enable CMPD down-count match enable event
  [8] CDU — Enable event time-base counter equal to CMPD when the timer is incrementing to the mixed ET SOCB trigger signal [ETSOCBMIX]. 0: CMPD up-count match enable event is not enabled 1: Enable CMPD up-count match enable event
  [7] CCD — Enable event time-base counter equal to CMPC when the timer is decrementing to the mixed ET SOCB trigger signal [ETSOCBMIX]. 0: CMPC down-count match enable event is not enabled 1: Enable CMPC down-count match enable event
  [6] CCU — Enable event time-base counter equal to CMPC when the timer is incrementing to the mixed ET SOCB trigger signal [ETSOCBMIX]. 0: CMPC up-count match enable event is not enabled 1: Enable CMPC up-count match enable event
  [5] CBD — Enable event time-base counter equal to CMPB when the timer is decrementing to the mixed ET SOCB trigger signal [ETSOCBMIX]. 0: CMPB down-count match enable event is not enabled 1: Enable CMPB down-count match enable event
  [4] CBU — Enable event time-base counter equal to CMPB when the timer is incrementing to the mixed ET SOCB trigger signal [ETSOCBMIX]. 0: CMPB up-count match enable event is not enabled 1: Enable CMPB up-count match enable event
  [3] CAD — Enable event time-base counter equal to CMPA when the timer is decrementing to the mixed ET SOCB trigger signal [ETSOCBMIX]. 0: CMPA down-count match enable event is not enabled 1: Enable CMPA down-count match enable event
  [2] CAU — Enable event time-base counter equal to CMPA when the timer is incrementing to the mixed ET SOCB trigger signal [ETSOCBMIX]. 0: CMPA up-count match enable event is not enabled 1: Enable CMPA up-count match enable event
  [1] PRD — Enable event time-base counter equal to period [TBCTR = TBPRD] to the mixed ET SOCB trigger signal [ETSOCBMIX]. 0: Period match event is not enabled 1: Enable period match event
  [0] ZRO — Enable event time-base counter equal to zero [TBCTR = 0x00] to the mixed ET SOCB trigger signal [ETSOCBMIX]. 0: Zero match event is not enabled 1: Enable zero match event
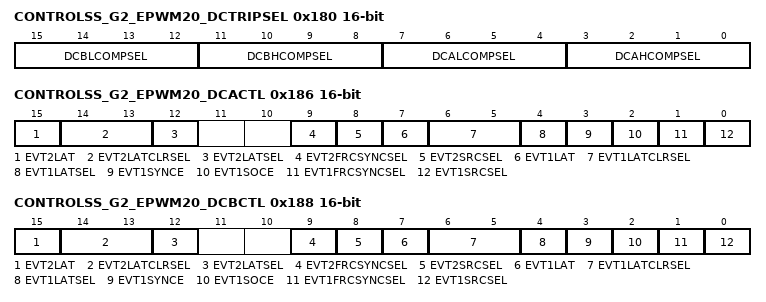
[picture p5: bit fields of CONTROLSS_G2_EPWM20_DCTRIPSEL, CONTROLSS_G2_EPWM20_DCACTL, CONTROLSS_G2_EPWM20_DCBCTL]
0x180 CONTROLSS_G2_EPWM20_DCTRIPSEL — Digital Compare Trip Select Register
  [15:12] DCBLCOMPSEL — Digital Compare B Low Input Select Bits 0000: TRIPIN1 0001: TRIPIN2 0010: TRIPIN3 0011: TRIPIN4 ... 1011: TRIPIN12 1100: Reserved 1101: TRIPIN14 1110: TRIPIN15 1111: Trip combination input [all trip inputs selected by DCBLTRIPSEL register ORed together]
  [11:8] DCBHCOMPSEL — Digital Compare B High Input Select Bits 0000: TRIPIN1 0001: TRIPIN2 0010: TRIPIN3 0011: TRIPIN4 ... 1011: TRIPIN12 1100: Reserved 1101: TRIPIN14 1110: TRIPIN15 1111: Trip combination input [all trip inputs selected by DCBHTRIPSEL register ORed together]
  [7:4] DCALCOMPSEL — Digital Compare A Low Input Select Bits 0000: TRIPIN1 0001: TRIPIN2 0010: TRIPIN3 0011: TRIPIN4 ... 1011: TRIPIN12 1100: Reserved 1101: TRIPIN14 1110: TRIPIN15 1111: Trip combination input [all trip inputs selected by DCALTRIPSEL register ORed together]
  [3:0] DCAHCOMPSEL — Digital Compare A High Input Select Bits 0000: TRIPIN1 0001: TRIPIN2 0010: TRIPIN3 0011: TRIPIN4 ... 1011: TRIPIN12 1100: Reserved 1101: TRIPIN14 1110: TRIPIN15 1111: Trip combination input [all trip inputs selected by DCAHTRIPSEL register ORed together]
0x186 CONTROLSS_G2_EPWM20_DCACTL access per field — Digital Compare A Control Register
  [15] EVT2LAT ro — Indicates the status of DCAEVT2LAT signal. 0 The DCAEVT2LAT latch is cleared. 1 The DCAEVT2LAT latch is set.
  [14:13] EVT2LATCLRSEL rw — DCAEVT2 Latched clear source select: 00 CNT_ZERO event clears DCAEVT2 latch. 01 PRD_EQ event clears DCAEVT2 latch. 10 CNT_ZERO event or PRD_EQ event clears DCAEVT2 latch. 11 Reserved.
  [12] EVT2LATSEL rw — DCAEVT2 Latched signal select: 0 Does not select the DCAEVT2 latched signal [Refer figure Modifications to DCAEVT1.force/DCAEVT2.force generation.] as source of DCAEVT2.force. 1 Selects the DCAEVT2 latched signal as source of DCAEVT2.force.
  [9] EVT2FRCSYNCSEL rw — DCAEVT2 Force Synchronization Signal Select 0: Source is synchronized with EPWMCLK 1: Source is passed through asynchronously
  [8] EVT2SRCSEL rw — DCAEVT2 Source Signal Select 0: Source Is DCAEVT2 Signal 1: Source Is DCEVTFILT Signal
  [7] EVT1LAT ro — Indicates the status of DCAEVT1LAT signal. 0 The DCAEVT1LAT latch is cleared. 1 The DCAEVT1LAT latch is set.
  [6:5] EVT1LATCLRSEL rw — DCAEVT1 Latched clear source select: 00 CNT_ZERO event clears DCAEVT1 latch. 01 PRD_EQ event clears DCAEVT1 latch. 10 CNT_ZERO event or PRD_EQ event clears DCAEVT1 latch. 11 Reserved.
  [4] EVT1LATSEL rw — DCAEVT1 Latched signal select: 0 Does not select the DCAEVT1 latched signal [Refer figure Modifications to DCAEVT1.force/DCAEVT2.force generation.] as source of DCAEVT1.force. 1 Selects the DCAEVT1 latched signal as source of DCAEVT1.force.
  [3] EVT1SYNCE rw — DCAEVT1 SYNC, Enable/Disable 0: SYNC Generation Disabled 1: SYNC Generation Enabled
  [2] EVT1SOCE rw — DCAEVT1 SOC, Enable/Disable 0: SOC Generation Disabled 1: SOC Generation Enabled
  [1] EVT1FRCSYNCSEL rw — DCAEVT1 Force Synchronization Signal Select 0: Source is synchronized with EPWMCLK 1: Source is passed through asynchronously
  [0] EVT1SRCSEL rw — DCAEVT1 Source Signal Select 0: Source Is DCAEVT1 Signal 1: Source Is DCEVTFILT Signal
0x188 CONTROLSS_G2_EPWM20_DCBCTL access per field — Digital Compare B Control Register
  [15] EVT2LAT ro — Indicates the status of DCBEVT2LAT signal. 0 The DCBEVT2LAT latch is cleared. 1 The DCBEVT2LAT latch is set.
  [14:13] EVT2LATCLRSEL rw — DCBEVT2 Latched clear source select: 00 CNT_ZERO event clears DCBEVT2 latch. 01 PRD_EQ event clears DCBEVT2 latch. 10 CNT_ZERO event or PRD_EQ event clears DCBEVT2 latch. 11 Reserved.
  [12] EVT2LATSEL rw — DCBEVT2 Latched signal select: 0 Does not select the DCBEVT2 latched signal [Refer figure Modifications to DCBEVT1.force/DCBEVT2.force generation.] as source of DCBEVT2.force. 1 Selects the DCBEVT2 latched signal as source of DCBEVT2.force.
  [9] EVT2FRCSYNCSEL rw — DCBEVT2 Force Synchronization Signal Select 0: Source is synchronized with EPWMCLK 1: Source is passed through asynchronously
  [8] EVT2SRCSEL rw — DCBEVT2 Source Signal Select 0: Source Is DCBEVT2 Signal 1: Source Is DCEVTFILT Signal
  [7] EVT1LAT ro — Indicates the status of DCBEVT1LAT signal. 0 The DCBEVT1LAT latch is cleared. 1 The DCBEVT1LAT latch is set.
  [6:5] EVT1LATCLRSEL rw — DCBEVT1 Latched clear source select: 00 CNT_ZERO event clears DCBEVT1 latch. 01 PRD_EQ event clears DCBEVT1 latch. 10 CNT_ZERO event or PRD_EQ event clears DCBEVT1 latch. 11 Reserved.
  [4] EVT1LATSEL rw — DCBEVT1 Latched signal select: 0 Does not select the DCBEVT1 latched signal [Refer figure Modifications to DCBEVT1.force/DCBEVT2.force generation.] as source of DCBEVT1.force. 1 Selects the DCBEVT1 latched signal as source of DCBEVT1.force.
  [3] EVT1SYNCE rw — DCBEVT1 SYNC, Enable/Disable 0: SYNC Generation Disabled 1: SYNC Generation Enabled
  [2] EVT1SOCE rw — DCBEVT1 SOC, Enable/Disable 0: SOC Generation Disabled 1: SOC Generation Enabled
  [1] EVT1FRCSYNCSEL rw — DCBEVT1 Force Synchronization Signal Select 0: Source is synchronized with EPWMCLK 1: Source is passed through asynchronously
  [0] EVT1SRCSEL rw — DCBEVT1 Source Signal Select 0: Source Is DCBEVT1 Signal 1: Source Is DCEVTFILT Signal
